# GD32E53x register map
File version: 1.0
CPU: CM33 r0p4, little endian, MPU, FPU, 4 interrupt priority bits
Registers are 32-bit, read-write, reset 0x0 unless marked. A register's access mark holds for its fields unless they carry their own. Offsets are from the block's base; [hi:lo] are bit positions; {n}, {i} and the like mark numbered series.

## HAU — HAU acceleration unit
Base 0x40023800
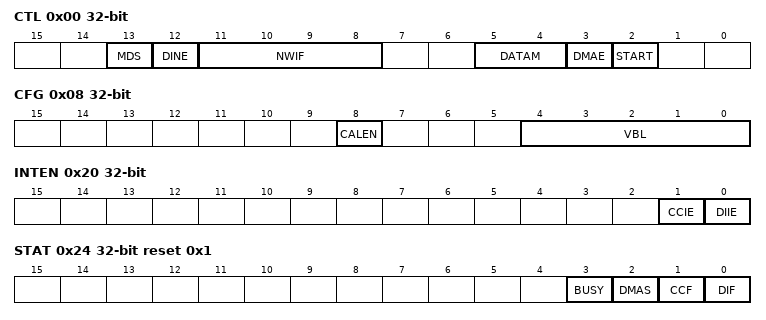
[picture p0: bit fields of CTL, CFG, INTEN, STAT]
0x00 CTL access per field — HAU control register
  [13] MDS rw — Multiple DMA selection
  [12] DINE ro — DI register is not empty
  [11:8] NWIF ro — Number of words in IN FIFO
  [5:4] DATAM rw — Data type mode
  [3] DMAE rw — DMA enable
  [2] START wo — Start message digest calculation
0x04 DI — HAU data input register
  [31:0] DI — Message data input
0x08 CFG access per field — HAU configuration register
  [8] CALEN wo — Digest calculation enable
  [4:0] VBL rw — Valid bits length in the last word
{0xC+4i} DO{i} ro (i=0..4) — HAU data output register
  [31:0] DO{i} — message digest result of hash algorithm
0x20 INTEN — HAU interrupt enable register
  [1] CCIE — calculation completion interrupt enable
  [0] DIIE — Data input interrupt enable
0x24 STAT ro reset 0x1 — HAU status and interrupt flag register
  [3] BUSY — Busy flag bit
  [2] DMAS — DMA status flag
  [1] CCF — Digest calculation completion flag
  [0] DIF — Data input flag
{0x310+4i} DO{i} ro (i=5..7) — HAU data output register
  [31:0] DO{i} — message digest result of hash algorithm

## ICACHE — Instruction cache
Base 0x40026000
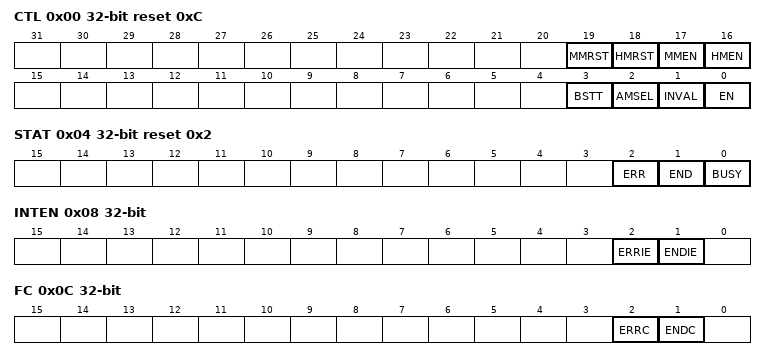
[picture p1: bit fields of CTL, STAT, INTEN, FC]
0x00 CTL access per field reset 0xC — Control register
  [19] MMRST rw — Miss monitor reset
  [18] HMRST rw — Hit monitor reset
  [17] MMEN rw — Miss monitor enable
  [16] HMEN rw — Hit monitor enable
  [3] BSTT rw — Burst type for fast bus 0: WRAP4 1: INCR4
  [2] AMSEL rw — Cache set-associativity mode selection
  [1] INVAL wo — Cache invalidation, set by software and cleared by hardware (BUSYF flag is set)
  [0] EN rw — Enable
0x04 STAT ro reset 0x2 — Status register
  [2] ERR — Cache error flag
  [1] END — Operation end flag
  [0] BUSY — Busy flag
0x08 INTEN — Interrupt enable register
  [2] ERRIE — Cache error interrupt enable
  [1] ENDIE — Cache operation end interrupt enable
0x0C FC wo — Flag clear register
  [2] ERRC — Software clear cache error flag
  [1] ENDC — Software clear operation end flag
0x10 HMC ro — Hit monitor counter register
  [31:0] HMC — Cache hit monitor counter.
0x14 MMC ro — Miss monitor counter register
  [15:0] MMC — Cache miss monitor counter
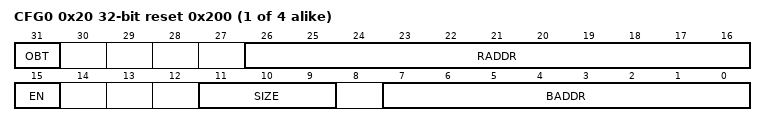
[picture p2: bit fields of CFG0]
{0x20+4i} CFG{i} reset 0x200 (i=0..3) — Configuration regist {i}
  [31] OBT — Output burst type for region x
  [26:16] RADDR — Region x remapped address, this field replaces the alias address defined by BADDR field.
  [15] EN — Region x enable
  [11:9] SIZE — Region x size
  [7:0] BADDR — Region x base address

## SPI0 — Serial peripheral interface/Inter-IC sound
Base 0x40013000
Same registers: I2S1_ADD 0x40003400, SPI1 0x40003800, SPI2 0x40003C00, I2S2_ADD 0x40004000, SPI3 0x40018400
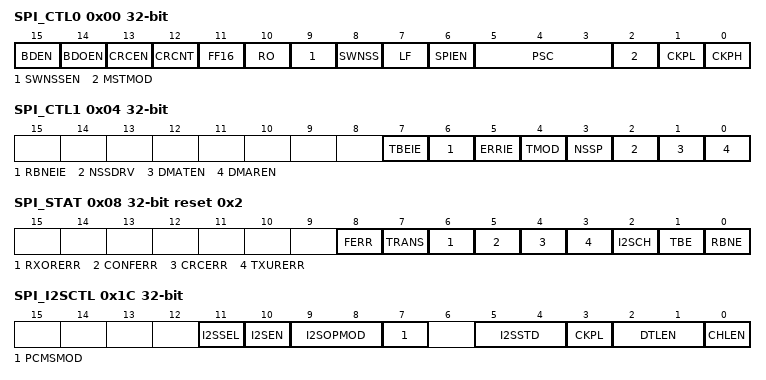
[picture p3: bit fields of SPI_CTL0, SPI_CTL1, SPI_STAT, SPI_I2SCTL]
0x00 SPI_CTL0 — Control register 0
  [15] BDEN — Bidirectional enable
  [14] BDOEN — Bidirectional transmit output enable
  [13] CRCEN — CRC calculation enable
  [12] CRCNT — CRC next transfer
  [11] FF16 — Data frame format
  [10] RO — Receive only
  [9] SWNSSEN — NSS software mode selection
  [8] SWNSS — NSS pin selection in NSS software mode
  [7] LF — LSB first mode
  [6] SPIEN — SPI enable
  [5:3] PSC — Master clock prescaler selection
  [2] MSTMOD — Master mode enable
  [1] CKPL — Clock polarity selection
  [0] CKPH — Clock phase selection
0x04 SPI_CTL1 — Control register 1
  [7] TBEIE — Transmit buffer empty interrupt enable
  [6] RBNEIE — Receive buffer not empty interrupt enable
  [5] ERRIE — Errors interrupt enable.
  [4] TMOD — SPI TI mode enable
  [3] NSSP — SPI NSS pulse mode enable
  [2] NSSDRV — Drive NSS output
  [1] DMATEN — Transmit buffer DMA enable
  [0] DMAREN — Receive buffer DMA enable
0x08 SPI_STAT access per field reset 0x2 — Status register
  [8] FERR rw — Format error bit
  [7] TRANS ro — Transmitting on-going bit
  [6] RXORERR ro — Reception overrun error bit
  [5] CONFERR ro — SPI configuration error bit
  [4] CRCERR rw — SPI CRC error bit
  [3] TXURERR ro — Transmission underrun error bit
  [2] I2SCH ro — I2S channel side
  [1] TBE ro — Transmit buffer empty
  [0] RBNE ro — Receive buffer not empty
0x0C SPI_DATA — Data register
  [15:0] SPI_DATA — Data transfer register
0x10 SPI_CRCPOLY reset 0x7 — CRC polynomial register
  [15:0] CRCPOLY
0x14 SPI_RCRC ro — RX CRC register
  [15:0] RCRC
0x18 SPI_TCRC ro — TX CRC register
  [15:0] TCRC
0x1C SPI_I2SCTL — I2S control register
  [11] I2SSEL — I2S mode selection
  [10] I2SEN — I2S enable
  [9:8] I2SOPMOD — I2S operation mode
  [7] PCMSMOD — PCM frame synchronization mode
  [5:4] I2SSTD — I2S standard selection
  [3] CKPL — Idle state clock polarity
  [2:1] DTLEN — Data length
  [0] CHLEN — Channel length
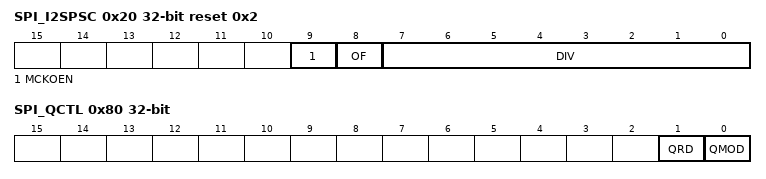
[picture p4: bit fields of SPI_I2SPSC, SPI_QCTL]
0x20 SPI_I2SPSC reset 0x2 — I2S clock prescaler register
  [9] MCKOEN — I2S_MCK output enable
  [8] OF — Odd factor for the prescaler
  [7:0] DIV — Dividing factor for the prescaler
0x80 SPI_QCTL — Quad-SPI mode control register
  [1] QRD — Quad-SPI mode read select.
  [0] QMOD — Quad-SPI mode enable
